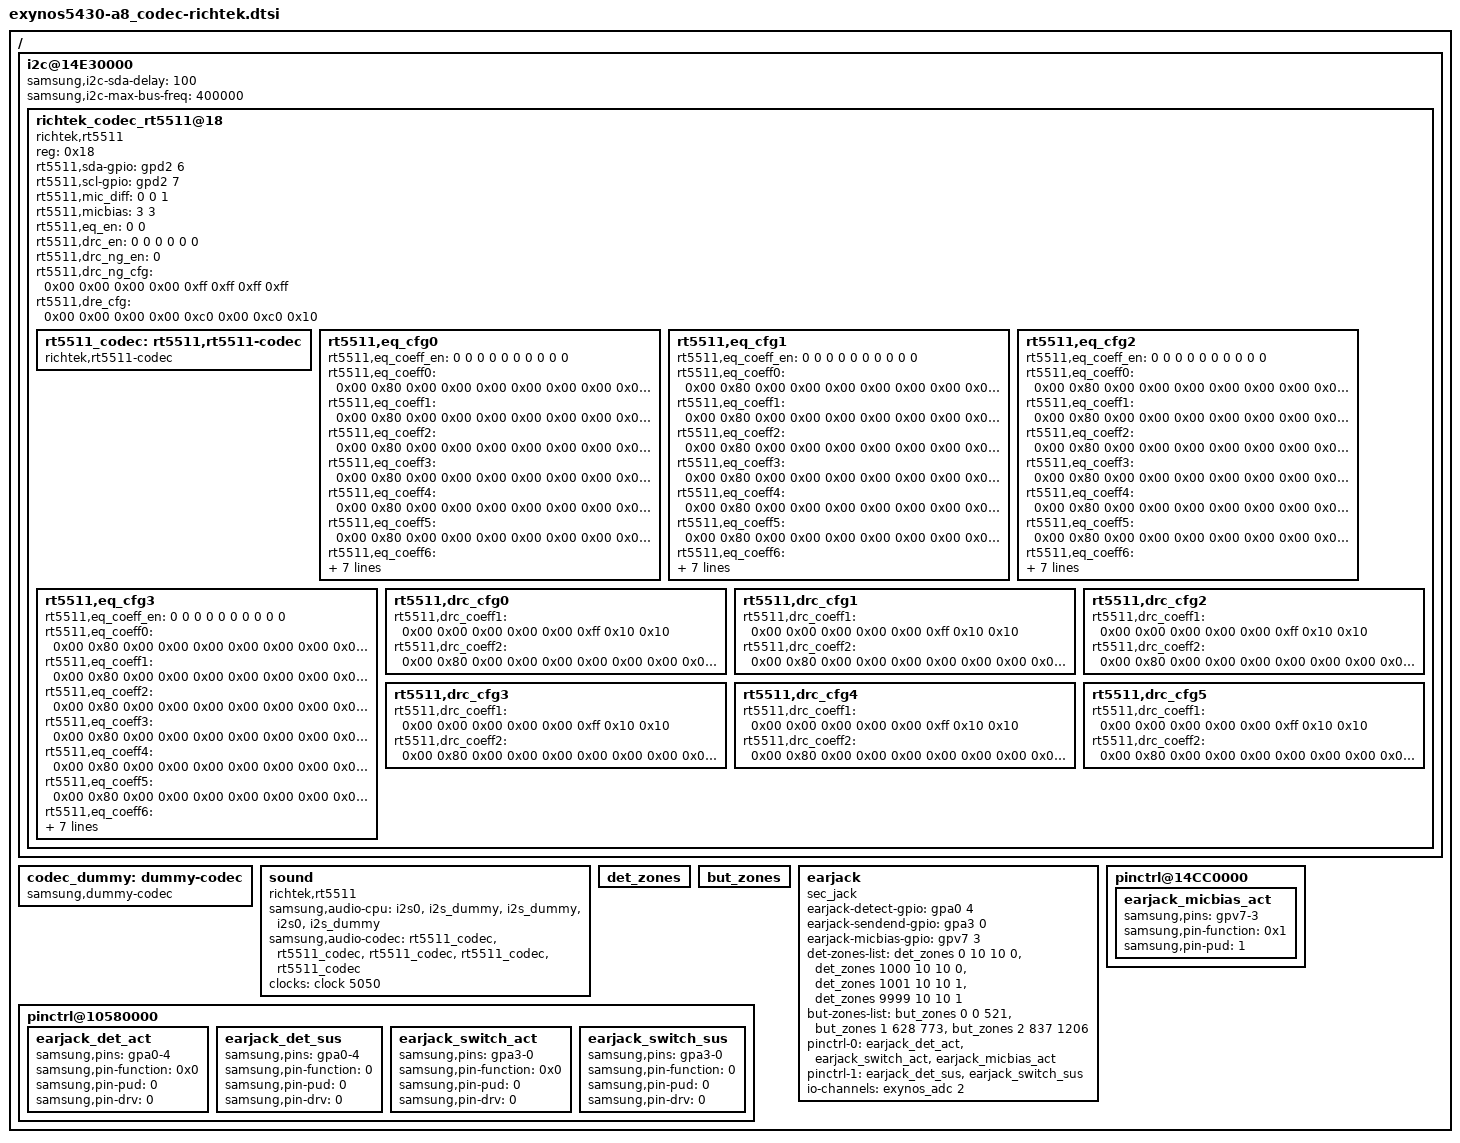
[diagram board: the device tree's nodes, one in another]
/*
 * SAMSUNG UNIVERSAL5430 board device tree source
 *
 * Copyright (c) 2013 Samsung Electronics Co., Ltd.
 *		http://www.samsung.com
 *
 * This program is free software; you can redistribute it and/or modify
 * it under the terms of the GNU General Public License version 2 as
 * published by the Free Software Foundation.
*/

/ {

	i2c@14E30000 {
		samsung,i2c-sda-delay = <100>;
		samsung,i2c-max-bus-freq = <400000>;
		status = "okay";

		richtek_codec_rt5511@18 {
			compatible = "richtek,rt5511";
			reg = <0x18>;
			rt5511,sda-gpio = <&gpd2 6 0>;
			rt5511,scl-gpio = <&gpd2 7 0>;

			rt5511,mic_diff = < 0 0 1 >;

			/* from 0 to 3, it means 1.9V, 2.2V, 2.5V 2.8V */
			rt5511,micbias = <3 3>;

			rt5511,eq_en = < 0 0 >;
			rt5511,drc_en = < 0 0 0 0 0 0 >;
			rt5511,drc_ng_en = <0>;

			rt5511,drc_ng_cfg = < 0x00 0x00 0x00 0x00 0xff 0xff 0xff 0xff >;
			rt5511,dre_cfg = < 0x00 0x00 0x00 0x00 0xc0 0x00 0xc0 0x10 >;

			rt5511_codec: rt5511,rt5511-codec {
				compatible = "richtek,rt5511-codec";
			};

			rt5511,eq_cfg0 {
				rt5511,eq_coeff_en = < 0 0 0 0 0 0 0 0 0 0 >;

				rt5511,eq_coeff0 = <
					0x00 0x80 0x00 0x00 0x00 0x00 0x00 0x00 0x00 0x00
					0x00 0x00 0x00 0x00 0x00 0x00 0x00 0x00 0x00 0x00 >;
				rt5511,eq_coeff1 = <
					0x00 0x80 0x00 0x00 0x00 0x00 0x00 0x00 0x00 0x00
					0x00 0x00 0x00 0x00 0x00 0x00 0x00 0x00 0x00 0x00 >;
				rt5511,eq_coeff2 = <
					0x00 0x80 0x00 0x00 0x00 0x00 0x00 0x00 0x00 0x00
					0x00 0x00 0x00 0x00 0x00 0x00 0x00 0x00 0x00 0x00 >;
				rt5511,eq_coeff3 = <
					0x00 0x80 0x00 0x00 0x00 0x00 0x00 0x00 0x00 0x00
					0x00 0x00 0x00 0x00 0x00 0x00 0x00 0x00 0x00 0x00 >;
				rt5511,eq_coeff4 = <
					0x00 0x80 0x00 0x00 0x00 0x00 0x00 0x00 0x00 0x00
					0x00 0x00 0x00 0x00 0x00 0x00 0x00 0x00 0x00 0x00 >;
				rt5511,eq_coeff5 = <
					0x00 0x80 0x00 0x00 0x00 0x00 0x00 0x00 0x00 0x00
					0x00 0x00 0x00 0x00 0x00 0x00 0x00 0x00 0x00 0x00 >;
				rt5511,eq_coeff6 = <
					0x00 0x80 0x00 0x00 0x00 0x00 0x00 0x00 0x00 0x00
					0x00 0x00 0x00 0x00 0x00 0x00 0x00 0x00 0x00 0x00 >;
				rt5511,eq_coeff7 = <
					0x00 0x80 0x00 0x00 0x00 0x00 0x00 0x00 0x00 0x00
					0x00 0x00 0x00 0x00 0x00 0x00 0x00 0x00 0x00 0x00 >;
				rt5511,eq_coeff8 = <
					0x00 0x80 0x00 0x00 0x00 0x00 0x00 0x00 0x00 0x00
					0x00 0x00 0x00 0x00 0x00 0x00 0x00 0x00 0x00 0x00 >;
				rt5511,eq_coeff9 = <
					0x00 0x80 0x00 0x00 0x00 0x00 0x00 0x00 0x00 0x00
					0x00 0x00 0x00 0x00 0x00 0x00 0x00 0x00 0x00 0x00 >;
			};

			rt5511,eq_cfg1 {
				rt5511,eq_coeff_en = < 0 0 0 0 0 0 0 0 0 0 >;

				rt5511,eq_coeff0 = <
					0x00 0x80 0x00 0x00 0x00 0x00 0x00 0x00 0x00 0x00
					0x00 0x00 0x00 0x00 0x00 0x00 0x00 0x00 0x00 0x00 >;
				rt5511,eq_coeff1 = <
					0x00 0x80 0x00 0x00 0x00 0x00 0x00 0x00 0x00 0x00
					0x00 0x00 0x00 0x00 0x00 0x00 0x00 0x00 0x00 0x00 >;
				rt5511,eq_coeff2 = <
					0x00 0x80 0x00 0x00 0x00 0x00 0x00 0x00 0x00 0x00
					0x00 0x00 0x00 0x00 0x00 0x00 0x00 0x00 0x00 0x00 >;
				rt5511,eq_coeff3 = <
					0x00 0x80 0x00 0x00 0x00 0x00 0x00 0x00 0x00 0x00
					0x00 0x00 0x00 0x00 0x00 0x00 0x00 0x00 0x00 0x00 >;
				rt5511,eq_coeff4 = <
					0x00 0x80 0x00 0x00 0x00 0x00 0x00 0x00 0x00 0x00
					0x00 0x00 0x00 0x00 0x00 0x00 0x00 0x00 0x00 0x00 >;
				rt5511,eq_coeff5 = <
					0x00 0x80 0x00 0x00 0x00 0x00 0x00 0x00 0x00 0x00
					0x00 0x00 0x00 0x00 0x00 0x00 0x00 0x00 0x00 0x00 >;
				rt5511,eq_coeff6 = <
					0x00 0x80 0x00 0x00 0x00 0x00 0x00 0x00 0x00 0x00
					0x00 0x00 0x00 0x00 0x00 0x00 0x00 0x00 0x00 0x00 >;
				rt5511,eq_coeff7 = <
					0x00 0x80 0x00 0x00 0x00 0x00 0x00 0x00 0x00 0x00
					0x00 0x00 0x00 0x00 0x00 0x00 0x00 0x00 0x00 0x00 >;
				rt5511,eq_coeff8 = <
					0x00 0x80 0x00 0x00 0x00 0x00 0x00 0x00 0x00 0x00
					0x00 0x00 0x00 0x00 0x00 0x00 0x00 0x00 0x00 0x00 >;
				rt5511,eq_coeff9 = <
					0x00 0x80 0x00 0x00 0x00 0x00 0x00 0x00 0x00 0x00
					0x00 0x00 0x00 0x00 0x00 0x00 0x00 0x00 0x00 0x00 >;
			};

			rt5511,eq_cfg2 {
				rt5511,eq_coeff_en = < 0 0 0 0 0 0 0 0 0 0 >;

				rt5511,eq_coeff0 = <
					0x00 0x80 0x00 0x00 0x00 0x00 0x00 0x00 0x00 0x00
					0x00 0x00 0x00 0x00 0x00 0x00 0x00 0x00 0x00 0x00 >;
				rt5511,eq_coeff1 = <
					0x00 0x80 0x00 0x00 0x00 0x00 0x00 0x00 0x00 0x00
					0x00 0x00 0x00 0x00 0x00 0x00 0x00 0x00 0x00 0x00 >;
				rt5511,eq_coeff2 = <
					0x00 0x80 0x00 0x00 0x00 0x00 0x00 0x00 0x00 0x00
					0x00 0x00 0x00 0x00 0x00 0x00 0x00 0x00 0x00 0x00 >;
				rt5511,eq_coeff3 = <
					0x00 0x80 0x00 0x00 0x00 0x00 0x00 0x00 0x00 0x00
					0x00 0x00 0x00 0x00 0x00 0x00 0x00 0x00 0x00 0x00 >;
				rt5511,eq_coeff4 = <
					0x00 0x80 0x00 0x00 0x00 0x00 0x00 0x00 0x00 0x00
					0x00 0x00 0x00 0x00 0x00 0x00 0x00 0x00 0x00 0x00 >;
				rt5511,eq_coeff5 = <
					0x00 0x80 0x00 0x00 0x00 0x00 0x00 0x00 0x00 0x00
					0x00 0x00 0x00 0x00 0x00 0x00 0x00 0x00 0x00 0x00 >;
				rt5511,eq_coeff6 = <
					0x00 0x80 0x00 0x00 0x00 0x00 0x00 0x00 0x00 0x00
					0x00 0x00 0x00 0x00 0x00 0x00 0x00 0x00 0x00 0x00 >;
				rt5511,eq_coeff7 = <
					0x00 0x80 0x00 0x00 0x00 0x00 0x00 0x00 0x00 0x00
					0x00 0x00 0x00 0x00 0x00 0x00 0x00 0x00 0x00 0x00 >;
				rt5511,eq_coeff8 = <
					0x00 0x80 0x00 0x00 0x00 0x00 0x00 0x00 0x00 0x00
					0x00 0x00 0x00 0x00 0x00 0x00 0x00 0x00 0x00 0x00 >;
				rt5511,eq_coeff9 = <
					0x00 0x80 0x00 0x00 0x00 0x00 0x00 0x00 0x00 0x00
					0x00 0x00 0x00 0x00 0x00 0x00 0x00 0x00 0x00 0x00 >;
			};

			rt5511,eq_cfg3 {
				rt5511,eq_coeff_en = < 0 0 0 0 0 0 0 0 0 0 >;

				rt5511,eq_coeff0 = <
					0x00 0x80 0x00 0x00 0x00 0x00 0x00 0x00 0x00 0x00
					0x00 0x00 0x00 0x00 0x00 0x00 0x00 0x00 0x00 0x00 >;
				rt5511,eq_coeff1 = <
					0x00 0x80 0x00 0x00 0x00 0x00 0x00 0x00 0x00 0x00
					0x00 0x00 0x00 0x00 0x00 0x00 0x00 0x00 0x00 0x00 >;
				rt5511,eq_coeff2 = <
					0x00 0x80 0x00 0x00 0x00 0x00 0x00 0x00 0x00 0x00
					0x00 0x00 0x00 0x00 0x00 0x00 0x00 0x00 0x00 0x00 >;
				rt5511,eq_coeff3 = <
					0x00 0x80 0x00 0x00 0x00 0x00 0x00 0x00 0x00 0x00
					0x00 0x00 0x00 0x00 0x00 0x00 0x00 0x00 0x00 0x00 >;
				rt5511,eq_coeff4 = <
					0x00 0x80 0x00 0x00 0x00 0x00 0x00 0x00 0x00 0x00
					0x00 0x00 0x00 0x00 0x00 0x00 0x00 0x00 0x00 0x00 >;
				rt5511,eq_coeff5 = <
					0x00 0x80 0x00 0x00 0x00 0x00 0x00 0x00 0x00 0x00
					0x00 0x00 0x00 0x00 0x00 0x00 0x00 0x00 0x00 0x00 >;
				rt5511,eq_coeff6 = <
					0x00 0x80 0x00 0x00 0x00 0x00 0x00 0x00 0x00 0x00
					0x00 0x00 0x00 0x00 0x00 0x00 0x00 0x00 0x00 0x00 >;
				rt5511,eq_coeff7 = <
					0x00 0x80 0x00 0x00 0x00 0x00 0x00 0x00 0x00 0x00
					0x00 0x00 0x00 0x00 0x00 0x00 0x00 0x00 0x00 0x00 >;
				rt5511,eq_coeff8 = <
					0x00 0x80 0x00 0x00 0x00 0x00 0x00 0x00 0x00 0x00
					0x00 0x00 0x00 0x00 0x00 0x00 0x00 0x00 0x00 0x00 >;
				rt5511,eq_coeff9 = <
					0x00 0x80 0x00 0x00 0x00 0x00 0x00 0x00 0x00 0x00
					0x00 0x00 0x00 0x00 0x00 0x00 0x00 0x00 0x00 0x00 >;
			};

			rt5511,drc_cfg0 {
				rt5511,drc_coeff1 = <
					0x00 0x00 0x00 0x00 0x00 0xff 0x10 0x10 >;
				rt5511,drc_coeff2 = <
					0x00 0x80 0x00 0x00 0x00 0x00 0x00 0x00
					0x00 0x80 0x00 0x00 0x00 0x80 0x00 0x00 >;
			};
			rt5511,drc_cfg1 {
				rt5511,drc_coeff1 = <
					0x00 0x00 0x00 0x00 0x00 0xff 0x10 0x10 >;
				rt5511,drc_coeff2 = <
					0x00 0x80 0x00 0x00 0x00 0x00 0x00 0x00
					0x00 0x80 0x00 0x00 0x00 0x80 0x00 0x00 >;
			};
			rt5511,drc_cfg2 {
				rt5511,drc_coeff1 = <
					0x00 0x00 0x00 0x00 0x00 0xff 0x10 0x10 >;
				rt5511,drc_coeff2 = <
					0x00 0x80 0x00 0x00 0x00 0x00 0x00 0x00
					0x00 0x80 0x00 0x00 0x00 0x80 0x00 0x00 >;
			};
			rt5511,drc_cfg3 {
				rt5511,drc_coeff1 = <
					0x00 0x00 0x00 0x00 0x00 0xff 0x10 0x10 >;
				rt5511,drc_coeff2 = <
					0x00 0x80 0x00 0x00 0x00 0x00 0x00 0x00
					0x00 0x80 0x00 0x00 0x00 0x80 0x00 0x00 >;
			};
			rt5511,drc_cfg4 {
				rt5511,drc_coeff1 = <
					0x00 0x00 0x00 0x00 0x00 0xff 0x10 0x10 >;
				rt5511,drc_coeff2 = <
					0x00 0x80 0x00 0x00 0x00 0x00 0x00 0x00
					0x00 0x80 0x00 0x00 0x00 0x80 0x00 0x00 >;
			};
			rt5511,drc_cfg5 {
				rt5511,drc_coeff1 = <
					0x00 0x00 0x00 0x00 0x00 0xff 0x10 0x10 >;
				rt5511,drc_coeff2 = <
					0x00 0x80 0x00 0x00 0x00 0x00 0x00 0x00
					0x00 0x80 0x00 0x00 0x00 0x80 0x00 0x00 >;
			};
		};
	};
	
	codec_dummy: dummy-codec {
		compatible = "samsung,dummy-codec";
		status = "okay";
	};

	sound {
		compatible = "richtek,rt5511";
		samsung,audio-cpu = <&i2s0		/* primary */
				     &i2s_dummy
				     &i2s_dummy
				     &i2s0		/* secondary */
				     &i2s_dummy>;
		samsung,audio-codec = <&rt5511_codec
				     &rt5511_codec
				     &rt5511_codec
				     &rt5511_codec
				     &rt5511_codec>;
		clocks = <&clock 5050>;
		clock-names = "mclk";
		status = "okay";
	};

	det_zones: det_zones {
		#list-det-cells = <4>;
	};

	but_zones: but_zones {
		#list-but-cells = <3>;
	};

	earjack {
		compatible = "sec_jack";
		earjack-detect-gpio = <&gpa0 4 0>;
		earjack-sendend-gpio = <&gpa3 0 0>;
		earjack-micbias-gpio = <&gpv7 3 0>;

		det-zones-list = <&det_zones 0 10 10 0>,
				 <&det_zones 1000 10 10 0>,
				 <&det_zones 1001 10 10 1>,
				 <&det_zones 9999 10 10 1>;
		but-zones-list = <&but_zones 0 0 521>,
				 <&but_zones 1 628 773>,
				 <&but_zones 2 837 1206>;
		pinctrl-names = "earjack_gpio_active","earjack_gpio_suspend";
		pinctrl-0 = <&earjack_det_act &earjack_switch_act &earjack_micbias_act>;
		pinctrl-1 = <&earjack_det_sus &earjack_switch_sus>;

		io-channels = <&exynos_adc 2>;
		io-channel-names = "adc-earjack";
	};

	pinctrl@10580000 {
		/* 3.5 pi Earjack */
		earjack_det_act: earjack_det_act {
			samsung,pins = "gpa0-4";
			samsung,pin-function = <0x0>;		/* IN */
			samsung,pin-pud = <0>;			/* No PULL */
			samsung,pin-drv = <0>;
		};
		earjack_det_sus: earjack_det_sus {
			samsung,pins = "gpa0-4";
			samsung,pin-function = <0>;		/* IN */
			samsung,pin-pud = <0>;			/* No PULL */
			samsung,pin-drv = <0>;
		};
	};

	pinctrl@10580000 {
		/* EAR_SEND_END */
		earjack_switch_act: earjack_switch_act {
			samsung,pins = "gpa3-0";
			samsung,pin-function = <0x0>;		/* IN */
			samsung,pin-pud = <0>;			/* No PULL */
			samsung,pin-drv = <0>;
		};
		earjack_switch_sus: earjack_switch_sus {
			samsung,pins = "gpa3-0";
			samsung,pin-function = <0>;		/* IN */
			samsung,pin-pud = <0>;			/* No PULL */
			samsung,pin-drv = <0>;
		};
	};

	pinctrl@14CC0000 {
		earjack_micbias_act: earjack_micbias_act {
				samsung,pins = "gpv7-3";
				samsung,pin-function = <0x1>;	/* OUT */
				samsung,pin-pud = <1>;		/* PULL DOWN */
		};
	};

};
